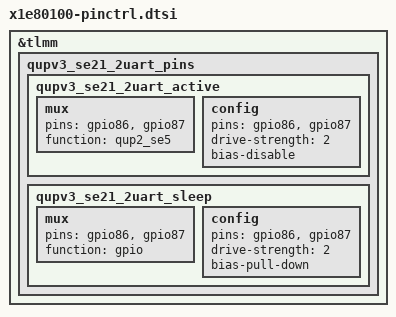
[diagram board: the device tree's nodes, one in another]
// SPDX-License-Identifier: BSD-3-Clause
/*
 * Copyright (c) Qualcomm Technologies, Inc. and/or its subsidiaries.
 */

&tlmm {
	qupv3_se21_2uart_pins: qupv3_se21_2uart_pins {
		qupv3_se21_2uart_active: qupv3_se21_2uart_active {
			mux {
				pins = "gpio86", "gpio87";
				function = "qup2_se5";
			};

			config {
				pins = "gpio86", "gpio87";
				drive-strength= <2>;
				bias-disable;
			};
		};

		qupv3_se21_2uart_sleep: qupv3_se21_2uart_sleep {
			mux {
				pins = "gpio86", "gpio87";
				function = "gpio";
			};

			config {
				pins = "gpio86", "gpio87";
				drive-strength = <2>;
				bias-pull-down;
			};
		};
	};
};
